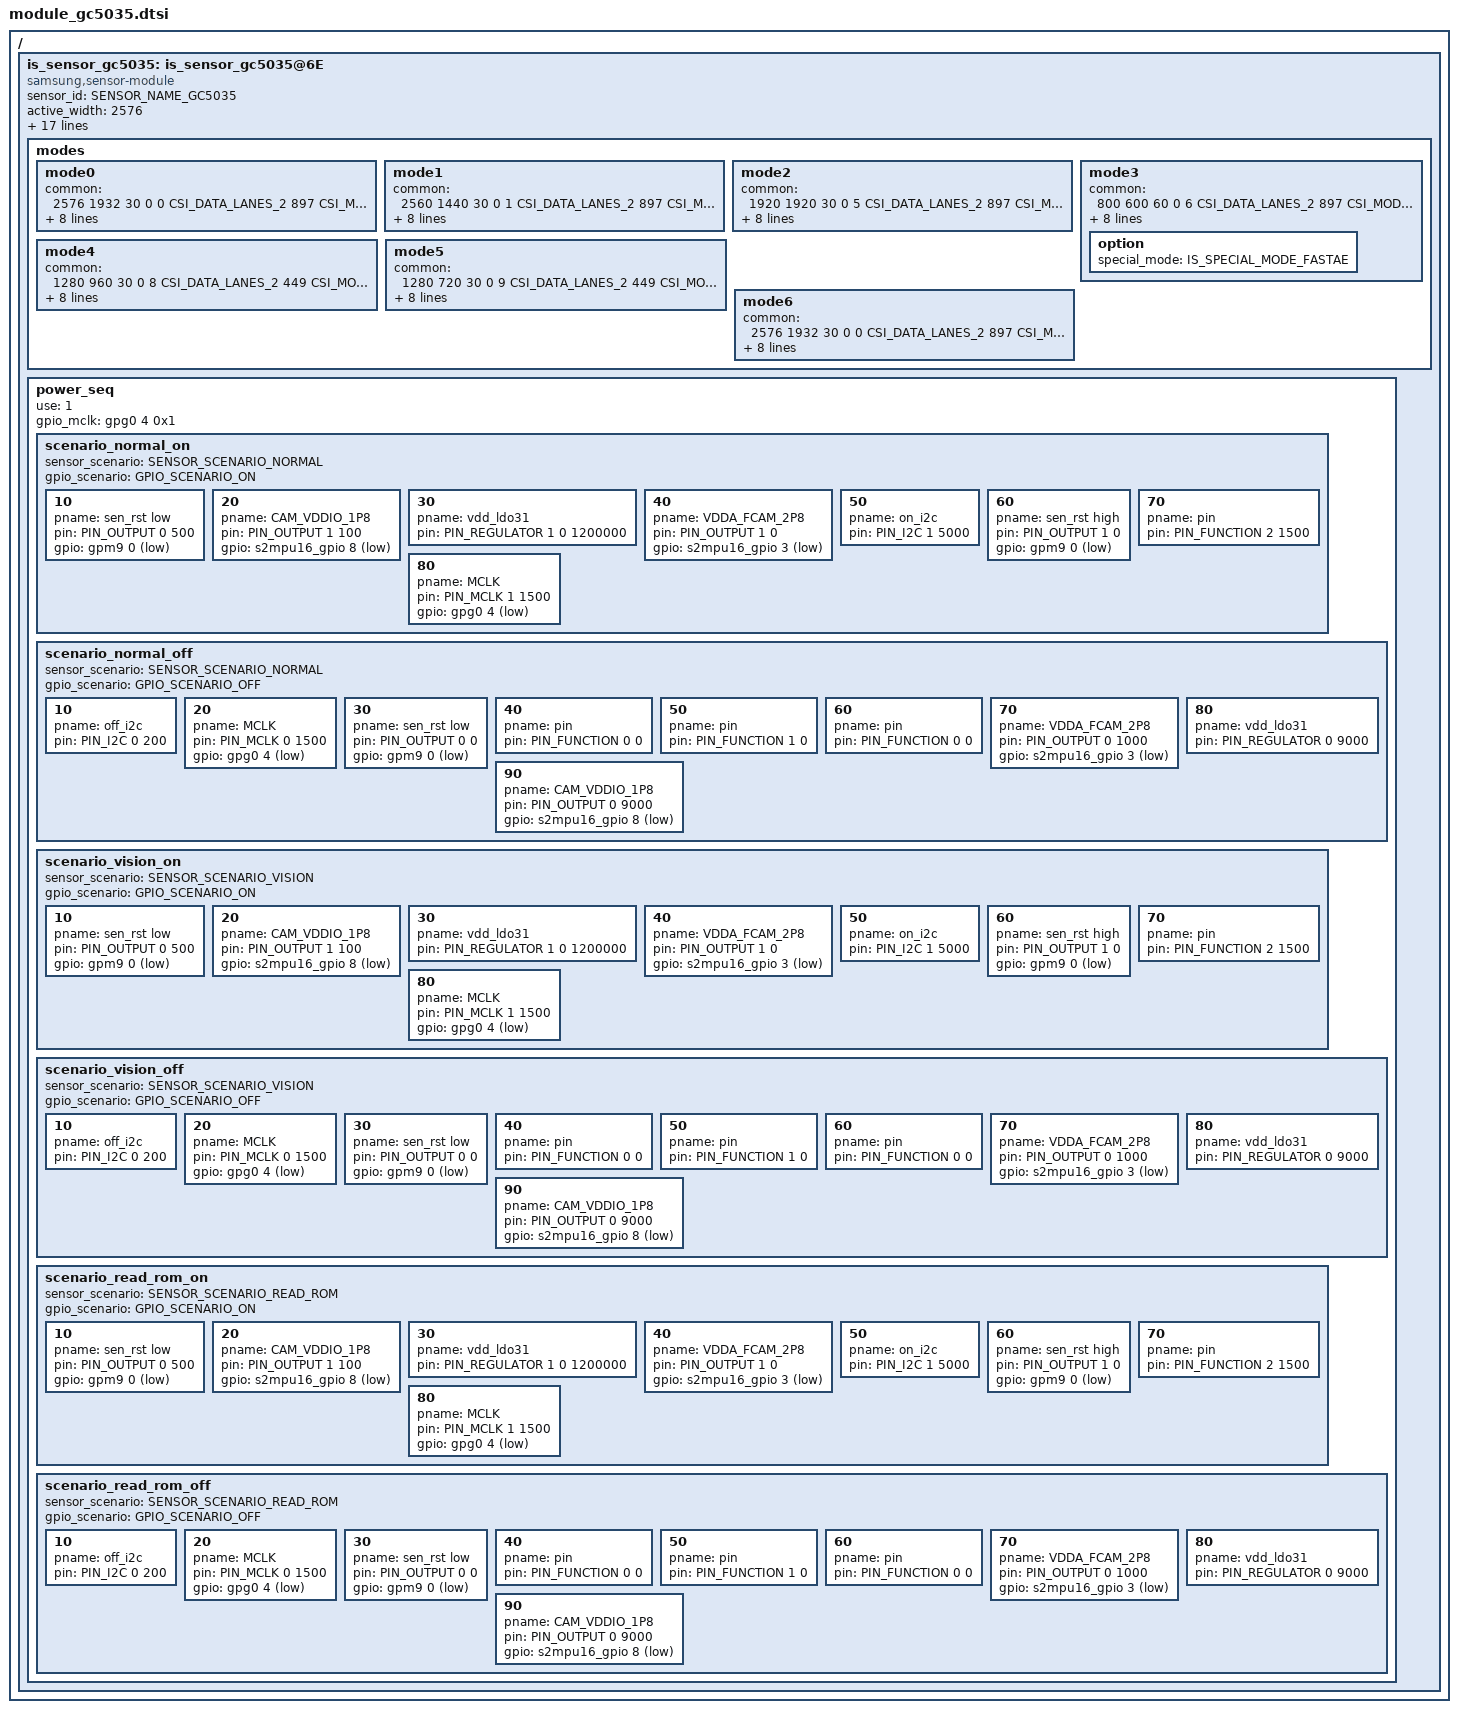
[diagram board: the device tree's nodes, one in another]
/*
 * SAMSUNG EXYNOSxxxx board camera device tree source
 *
 * Copyright (c) 2022 Samsung Electronics Co., Ltd.
 *		http://www.samsung.com
 *
 * This program is free software; you can redistribute it and/or modify
 * it under the terms of the GNU General Public License version 2 as
 * published by the Free Software Foundation.
 */

#include <dt-bindings/camera/exynos_is_dt.h>


/ {
	fragment@camera {
		target-path = "/";
		__overlay__ {
			is_sensor_gc5035: is_sensor_gc5035@6E {
				compatible = "samsung,sensor-module";

				/* common */
				sensor_id = <SENSOR_NAME_GC5035>;
				active_width = <2576>;
				active_height = <1932>;
				margin_left = <0>;
				margin_right = <0>;
				margin_top = <0>;
				margin_bottom = <0>;
				max_framerate = <120>;
				bitwidth = <10>;
				use_retention_mode = <SENSOR_RETENTION_UNSUPPORTED>;
				sensor_maker = "GALAXYCORE";
				sensor_name = "GC5035";
				setfile_name = "setfile_gc5035.bin";
				pinning_setfile;
				preload_setfile;

				status = "okay";

				/* vendor */
				rom_type = <3>; /* ROM_TYPE_OTPROM */
				rom_id = <1>;
				rom_cal_index = <0>;

				/* sensor modes */
				modes {
						/* common = <width, height, fps, settle, mode, lane, speed, interleave, lrte, pd_mode> */
						/* vcX = <map, hwformat, width, height, hwformat, type, width, height> */

					/* 0 : 2576x1932@30fps 4:3 */
					mode0 {
						common = <2576 1932 30 0 0 CSI_DATA_LANES_2 897 CSI_MODE_VC_ONLY LRTE_DISABLE PD_NONE EX_NONE>;
						vc0 = </* in */ 0 HW_FORMAT_RAW10 2576 1932	/* out */ HW_FORMAT_RAW10 VC_NOTHING 2576 1932>;
						vc1 = </* in */ 1 HW_FORMAT_UNKNOWN 0 0		/* out */ HW_FORMAT_UNKNOWN VC_NOTHING 0 0>;
						vc2 = </* in */ 2 HW_FORMAT_UNKNOWN 0 0		/* out */ HW_FORMAT_UNKNOWN VC_NOTHING 0 0>;
						vc3 = </* in */ 3 HW_FORMAT_UNKNOWN 0 0		/* out */ HW_FORMAT_UNKNOWN VC_NOTHING 0 0>;
					};
					mode1 {
						common = <2560 1440 30 0 1 CSI_DATA_LANES_2 897 CSI_MODE_VC_ONLY LRTE_DISABLE PD_NONE EX_NONE>;
						vc0 = </* in */ 0 HW_FORMAT_RAW10 2560 1440	/* out */ HW_FORMAT_RAW10 VC_NOTHING 2560 1440>;
						vc1 = </* in */ 1 HW_FORMAT_UNKNOWN 0 0		/* out */ HW_FORMAT_UNKNOWN VC_NOTHING 0 0>;
						vc2 = </* in */ 2 HW_FORMAT_UNKNOWN 0 0		/* out */ HW_FORMAT_UNKNOWN VC_NOTHING 0 0>;
						vc3 = </* in */ 3 HW_FORMAT_UNKNOWN 0 0		/* out */ HW_FORMAT_UNKNOWN VC_NOTHING 0 0>;
					};
					mode2 {
						common = <1920 1920 30 0 5 CSI_DATA_LANES_2 897 CSI_MODE_VC_ONLY LRTE_DISABLE PD_NONE EX_NONE>;
						vc0 = </* in */ 0 HW_FORMAT_RAW10 1920 1920	/* out */ HW_FORMAT_RAW10 VC_NOTHING 1920 1920>;
						vc1 = </* in */ 1 HW_FORMAT_UNKNOWN 0 0		/* out */ HW_FORMAT_UNKNOWN VC_NOTHING 0 0>;
						vc2 = </* in */ 2 HW_FORMAT_UNKNOWN 0 0		/* out */ HW_FORMAT_UNKNOWN VC_NOTHING 0 0>;
						vc3 = </* in */ 3 HW_FORMAT_UNKNOWN 0 0		/* out */ HW_FORMAT_UNKNOWN VC_NOTHING 0 0>;
					};
					/* 3 : 800x600@60fps 4:3 */
					mode3 {
						common = <800 600 60 0 6 CSI_DATA_LANES_2 897 CSI_MODE_VC_ONLY LRTE_DISABLE PD_NONE EX_NONE>;
						vc0 = </* in */ 0 HW_FORMAT_RAW10 800 600	/* out */ HW_FORMAT_RAW10 VC_NOTHING 800 600>;
						vc1 = </* in */ 1 HW_FORMAT_UNKNOWN 0 0		/* out */ HW_FORMAT_UNKNOWN VC_NOTHING 0 0>;
						vc2 = </* in */ 2 HW_FORMAT_UNKNOWN 0 0		/* out */ HW_FORMAT_UNKNOWN VC_NOTHING 0 0>;
						vc3 = </* in */ 3 HW_FORMAT_UNKNOWN 0 0		/* out */ HW_FORMAT_UNKNOWN VC_NOTHING 0 0>;
						option { special_mode = <IS_SPECIAL_MODE_FASTAE>; };
					};
					mode4 {
						common = <1280 960 30 0 8 CSI_DATA_LANES_2 449 CSI_MODE_VC_ONLY LRTE_DISABLE PD_NONE EX_NONE>;
						vc0 = </* in */ 0 HW_FORMAT_RAW10 1280 960	/* out */ HW_FORMAT_RAW10 VC_NOTHING 1280 960>;
						vc1 = </* in */ 1 HW_FORMAT_UNKNOWN 0 0		/* out */ HW_FORMAT_UNKNOWN VC_NOTHING 0 0>;
						vc2 = </* in */ 2 HW_FORMAT_UNKNOWN 0 0		/* out */ HW_FORMAT_UNKNOWN VC_NOTHING 0 0>;
						vc3 = </* in */ 3 HW_FORMAT_UNKNOWN 0 0		/* out */ HW_FORMAT_UNKNOWN VC_NOTHING 0 0>;
					};
					mode5 {
						common = <1280 720 30 0 9 CSI_DATA_LANES_2 449 CSI_MODE_VC_ONLY LRTE_DISABLE PD_NONE EX_NONE>;
						vc0 = </* in */ 0 HW_FORMAT_RAW10 1280 720	/* out */ HW_FORMAT_RAW10 VC_NOTHING 1280 720>;
						vc1 = </* in */ 1 HW_FORMAT_UNKNOWN 0 0		/* out */ HW_FORMAT_UNKNOWN VC_NOTHING 0 0>;
						vc2 = </* in */ 2 HW_FORMAT_UNKNOWN 0 0		/* out */ HW_FORMAT_UNKNOWN VC_NOTHING 0 0>;
						vc3 = </* in */ 3 HW_FORMAT_UNKNOWN 0 0		/* out */ HW_FORMAT_UNKNOWN VC_NOTHING 0 0>;
					};
					mode6 {
						// FOR SECURE CAMERA FD SCENARIO
						common = <2576 1932 30 0 0 CSI_DATA_LANES_2 897 CSI_MODE_VC_ONLY LRTE_DISABLE PD_NONE EX_PDSTAT_OFF>;
						vc0 = </* in */ 0 HW_FORMAT_RAW10 2576 1932	/* out */ HW_FORMAT_RAW10 VC_NOTHING 1288 966>;
						vc1 = </* in */ 1 HW_FORMAT_UNKNOWN 0 0		/* out */ HW_FORMAT_UNKNOWN VC_NOTHING 0 0>;
						vc2 = </* in */ 2 HW_FORMAT_UNKNOWN 0 0		/* out */ HW_FORMAT_UNKNOWN VC_NOTHING 0 0>;
						vc3 = </* in */ 3 HW_FORMAT_UNKNOWN 0 0		/* out */ HW_FORMAT_UNKNOWN VC_NOTHING 0 0>;
					};
				};

				power_seq {
					use = <1>;
					gpio_mclk = <&gpg0 4 0x1>;
					scenario_normal_on {
						sensor_scenario = <SENSOR_SCENARIO_NORMAL>;
						gpio_scenario = <GPIO_SCENARIO_ON>;

						/* A start node number should be over the 10 for reserved number 0~9. */
						/* pname = "name"; pin = <act value delay voltage>; gpio = <gpx# # 0x1>; */
						10 { pname = "sen_rst low"; pin = <PIN_OUTPUT 0 500>; gpio = <&gpm9 0 0x1>; };
						20 { pname = "CAM_VDDIO_1P8"; pin = <PIN_OUTPUT 1 100>; gpio = <&s2mpu16_gpio 8 0x1>;};
						30 { pname = "vdd_ldo31"; pin = <PIN_REGULATOR 1 0 1200000>; };
						40 { pname = "VDDA_FCAM_2P8"; pin = <PIN_OUTPUT 1 0>; gpio = <&s2mpu16_gpio 3 0x1>;};
						50 { pname = "on_i2c"; pin = <PIN_I2C 1 5000>; };
						60 { pname = "sen_rst high"; pin = <PIN_OUTPUT 1 0>; gpio = <&gpm9 0 0x1>; };
						70 { pname = "pin"; pin = <PIN_FUNCTION 2 1500>; };
						80 { pname = "MCLK"; pin = <PIN_MCLK 1 1500>; gpio = <&gpg0 4 0x1>; };
					};

					scenario_normal_off {
						sensor_scenario = <SENSOR_SCENARIO_NORMAL>;
						gpio_scenario = <GPIO_SCENARIO_OFF>;

						/* A start node number should be over the 10 for reserved number 0~9. */
						/* pname = "name"; pin = <act value delay voltage>; gpio = <gpx# # 0x1>; */
						10 { pname = "off_i2c"; pin = <PIN_I2C 0 200>; };
						20 { pname = "MCLK"; pin = <PIN_MCLK 0 1500>; gpio = <&gpg0 4 0x1>; };
						30 { pname = "sen_rst low"; pin = <PIN_OUTPUT 0 0>; gpio = <&gpm9 0 0x1>; };
						40 { pname = "pin"; pin = <PIN_FUNCTION 0 0>; };
						50 { pname = "pin"; pin = <PIN_FUNCTION 1 0>; };
						60 { pname = "pin"; pin = <PIN_FUNCTION 0 0>; };
						70 { pname = "VDDA_FCAM_2P8"; pin = <PIN_OUTPUT 0 1000>; gpio = <&s2mpu16_gpio 3 0x1>;};
						80 { pname = "vdd_ldo31"; pin = <PIN_REGULATOR 0 9000>; };
						90 { pname = "CAM_VDDIO_1P8"; pin = <PIN_OUTPUT 0 9000>; gpio = <&s2mpu16_gpio 8 0x1>;};
					};

					scenario_vision_on {
						sensor_scenario = <SENSOR_SCENARIO_VISION>;
						gpio_scenario = <GPIO_SCENARIO_ON>;

						/* A start node number should be over the 10 for reserved number 0~9. */
						/* pname = "name"; pin = <act value delay voltage>; gpio = <gpx# # 0x1>; */
						10 { pname = "sen_rst low"; pin = <PIN_OUTPUT 0 500>; gpio = <&gpm9 0 0x1>; };
						20 { pname = "CAM_VDDIO_1P8"; pin = <PIN_OUTPUT 1 100>; gpio = <&s2mpu16_gpio 8 0x1>;};
						30 { pname = "vdd_ldo31"; pin = <PIN_REGULATOR 1 0 1200000>; };
						40 { pname = "VDDA_FCAM_2P8"; pin = <PIN_OUTPUT 1 0>; gpio = <&s2mpu16_gpio 3 0x1>;};
						50 { pname = "on_i2c"; pin = <PIN_I2C 1 5000>; };
						60 { pname = "sen_rst high"; pin = <PIN_OUTPUT 1 0>; gpio = <&gpm9 0 0x1>; };
						70 { pname = "pin"; pin = <PIN_FUNCTION 2 1500>; };
						80 { pname = "MCLK"; pin = <PIN_MCLK 1 1500>; gpio = <&gpg0 4 0x1>; };
					};

					scenario_vision_off {
						sensor_scenario = <SENSOR_SCENARIO_VISION>;
						gpio_scenario = <GPIO_SCENARIO_OFF>;

						/* A start node number should be over the 10 for reserved number 0~9. */
						/* pname = "name"; pin = <act value delay voltage>; gpio = <gpx# # 0x1>; */
						10 { pname = "off_i2c"; pin = <PIN_I2C 0 200>; };
						20 { pname = "MCLK"; pin = <PIN_MCLK 0 1500>; gpio = <&gpg0 4 0x1>; };
						30 { pname = "sen_rst low"; pin = <PIN_OUTPUT 0 0>; gpio = <&gpm9 0 0x1>; };
						40 { pname = "pin"; pin = <PIN_FUNCTION 0 0>; };
						50 { pname = "pin"; pin = <PIN_FUNCTION 1 0>; };
						60 { pname = "pin"; pin = <PIN_FUNCTION 0 0>; };
						70 { pname = "VDDA_FCAM_2P8"; pin = <PIN_OUTPUT 0 1000>; gpio = <&s2mpu16_gpio 3 0x1>;};
						80 { pname = "vdd_ldo31"; pin = <PIN_REGULATOR 0 9000>; };
						90 { pname = "CAM_VDDIO_1P8"; pin = <PIN_OUTPUT 0 9000>; gpio = <&s2mpu16_gpio 8 0x1>;};
					};

					scenario_read_rom_on {
						sensor_scenario = <SENSOR_SCENARIO_READ_ROM>;
						gpio_scenario = <GPIO_SCENARIO_ON>;

						/* A start node number should be over the 10 for reserved number 0~9. */
						/* pname = "name"; pin = <act value delay voltage>; gpio = <gpx# # 0x1>; */
						10 { pname = "sen_rst low"; pin = <PIN_OUTPUT 0 500>; gpio = <&gpm9 0 0x1>; };
						20 { pname = "CAM_VDDIO_1P8"; pin = <PIN_OUTPUT 1 100>; gpio = <&s2mpu16_gpio 8 0x1>;};
						30 { pname = "vdd_ldo31"; pin = <PIN_REGULATOR 1 0 1200000>; };
						40 { pname = "VDDA_FCAM_2P8"; pin = <PIN_OUTPUT 1 0>; gpio = <&s2mpu16_gpio 3 0x1>;};
						50 { pname = "on_i2c"; pin = <PIN_I2C 1 5000>; };
						60 { pname = "sen_rst high"; pin = <PIN_OUTPUT 1 0>; gpio = <&gpm9 0 0x1>; };
						70 { pname = "pin"; pin = <PIN_FUNCTION 2 1500>; };
						80 { pname = "MCLK"; pin = <PIN_MCLK 1 1500>; gpio = <&gpg0 4 0x1>; };
					};

					scenario_read_rom_off {
						sensor_scenario = <SENSOR_SCENARIO_READ_ROM>;
						gpio_scenario = <GPIO_SCENARIO_OFF>;

						/* A start node number should be over the 10 for reserved number 0~9. */
						/* pname = "name"; pin = <act value delay voltage>; gpio = <gpx# # 0x1>; */
						10 { pname = "off_i2c"; pin = <PIN_I2C 0 200>; };
						20 { pname = "MCLK"; pin = <PIN_MCLK 0 1500>; gpio = <&gpg0 4 0x1>; };
						30 { pname = "sen_rst low"; pin = <PIN_OUTPUT 0 0>; gpio = <&gpm9 0 0x1>; };
						40 { pname = "pin"; pin = <PIN_FUNCTION 0 0>; };
						50 { pname = "pin"; pin = <PIN_FUNCTION 1 0>; };
						60 { pname = "pin"; pin = <PIN_FUNCTION 0 0>; };
						70 { pname = "VDDA_FCAM_2P8"; pin = <PIN_OUTPUT 0 1000>; gpio = <&s2mpu16_gpio 3 0x1>;};
						80 { pname = "vdd_ldo31"; pin = <PIN_REGULATOR 0 9000>; };
						90 { pname = "CAM_VDDIO_1P8"; pin = <PIN_OUTPUT 0 9000>; gpio = <&s2mpu16_gpio 8 0x1>;};
					};
				};
			};
		}; /* end of __overlay__ */

	}; /* end of fragment */
}; /* end of root */
